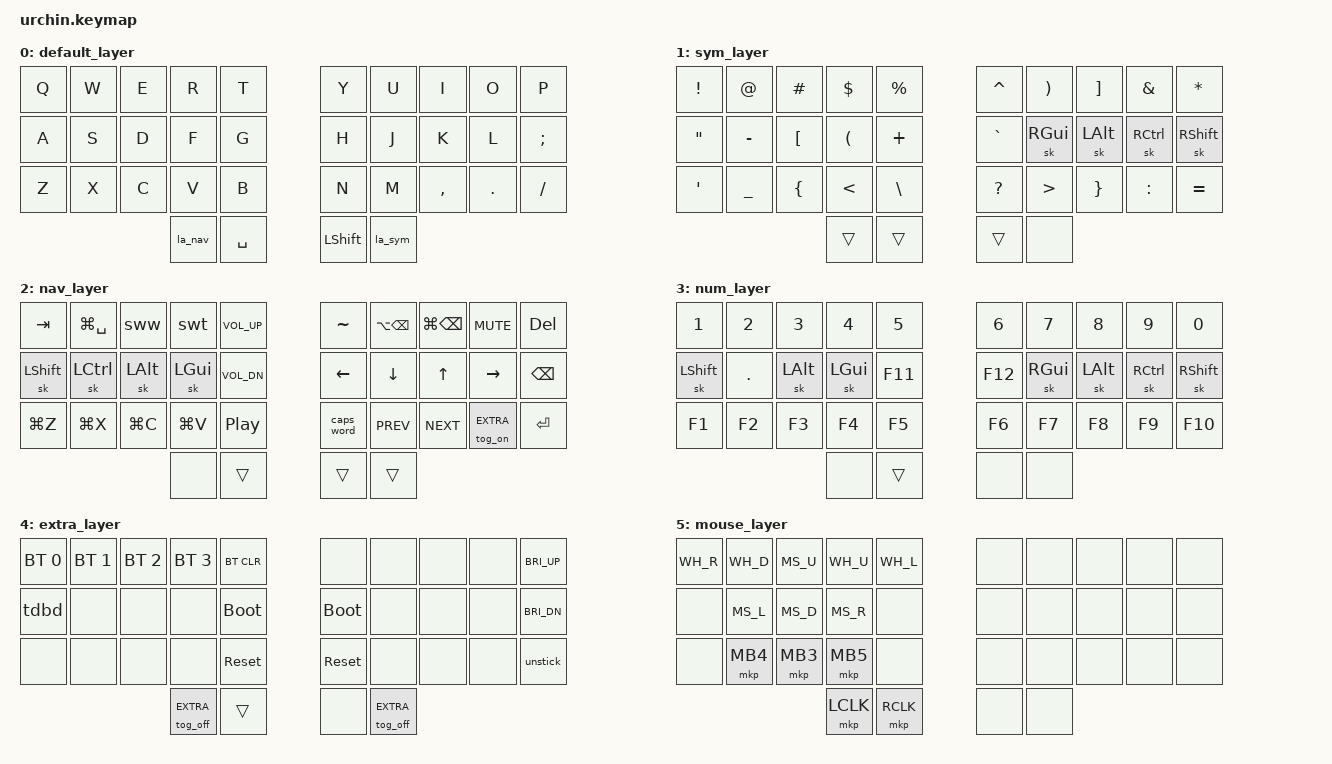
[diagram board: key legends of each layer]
#include <behaviors.dtsi>
#include <dt-bindings/zmk/keys.h>
#include <dt-bindings/zmk/bt.h>
#include <dt-bindings/zmk/outputs.h>
#include <dt-bindings/zmk/keys.h>
#include "mouse.dtsi"

// Layers from the QMK config
#define BASE  0
#define SYM   1
#define NAV   2
#define NUM   3
#define EXTRA 4
#define MOUSE 5

// QMK-ish aliases
#define XXX &none
#define ___ &trans

#define CMDBSPC  &kp LG(BSPC)
#define ALTBSPC  &kp LA(BSPC)
#define CMDZ     &kp LG(Z)
#define CMDX     &kp LG(X)
#define CMDC     &kp LG(C)
#define CMDV     &kp LG(V)
#define SWPL     &kp LG(SPACE)

&caps_word {
    continue-list = <MINUS BSPC DEL UNDER F22>; // F22 is required for layers
};

&sk {
    release-after-ms = <100000000>; // indefinite
    quick-release; // modifiers are ignored so that would not become a problem
	ignore-modifiers;
};

/ {
    combos {
        compatible = "zmk,combos";
        combo_weEsc {
            timeout-ms = <40>;
            require-prior-idle-ms = <150>;
            key-positions = <1 2>; // we
            bindings = <&kp ESC>;
            layers = <BASE>;
        };

        combo_hjGJ {
            timeout-ms = <40>;
            require-prior-idle-ms = <150>;
            key-positions = <15 16>; // hj
            bindings = <&kp LG(J)>;
            layers = <BASE>;
        };

        combo_wrMouse {
            timeout-ms = <40>;
            require-prior-idle-ms = <200>;
            key-positions = <1 3>; // wr
            bindings = <&smart_mouse>;
            layers = <BASE>;
            slow-release;
        };

        combo_uoExtra {
            timeout-ms = <40>;
            require-prior-idle-ms = <200>;
            key-positions = <6 8>; // uo
            bindings = <&tog EXTRA>;
            slow-release;
        };
    };

    macros {
        la_nav: cancel_queued_os_mods_and_toggle_nav {
            compatible = "zmk,behavior-macro";
            #binding-cells = <0>;
            bindings
                = <&macro_press &mo NAV>
                , <&macro_tap &kp F22>
                , <&macro_pause_for_release>
                , <&macro_release &mo NAV>
                ;
        };

        la_sym: cancel_queued_os_mods_and_toggle_sym {
            compatible = "zmk,behavior-macro";
            #binding-cells = <0>;
            bindings
                = <&macro_press &mo SYM>
                , <&macro_tap &kp F22>
                , <&macro_pause_for_release>
                , <&macro_release &mo SYM>
                ;
        };

		unstick: unstick_mods {
			compatible = "zmk,behavior-macro";
			#binding-cells = <0>;
			bindings = <&kp LSHIFT &kp RSHIFT &kp LCTRL &kp RCTRL &kp LALT &kp RALT &kp LGUI &kp RGUI>;
		};
    };

    behaviors {
        sww: swap_window {
            compatible = "zmk,behavior-tri-state";
            #binding-cells = <0>;
            bindings = <&kt LGUI>, <&kp TAB>, <&kt LGUI>;
            ignored-key-positions = <10 32>; // left hand shift, right thumb shift
        };

        swt: swap_tab {
            compatible = "zmk,behavior-tri-state";
            #binding-cells = <0>;
            bindings = <&kt LCTRL>, <&kp TAB>, <&kt LCTRL>;
            ignored-key-positions = <10 32>;
        };

        smart_mouse: smart_mouse {
            compatible = "zmk,behavior-tri-state";
            #binding-cells = <0>;
            bindings = <&tog MOUSE>, <XXX>, <&tog MOUSE>;
            ignored-key-positions = <30 31 0 1 2 3 4 11 12 13 21 22 23>;
            ignored-layers = <MOUSE>;
        };

        tdbd: tap_dance_bt_disable {
            compatible = "zmk,behavior-tap-dance";
            #binding-cells = <0>;
            tapping-term-ms = <200>;
            bindings = <&bt BT_DISC 0>, <&bt BT_DISC 1>, <&bt BT_DISC 2>, <&bt BT_DISC 3>;
        };

        tog_on: toggle_layer_on_only {
            compatible = "zmk,behavior-toggle-layer";
            #binding-cells = <1>;
            toggle-mode = "on";
        };

        tog_off: toggle_layer_off_only {
            compatible = "zmk,behavior-toggle-layer";
            #binding-cells = <1>;
            toggle-mode = "off";
        };
    };

    conditional_layers {
        compatible = "zmk,conditional-layers";
        tri_layer {
            if-layers = <SYM NAV>;
            then-layer = <NUM>;
        };
    };

    keymap {
        compatible = "zmk,keymap";
		default_layer {
			bindings = <
			&kp Q &kp W &kp E &kp R &kp T           &kp Y &kp U  &kp I     &kp O   &kp P
			&kp A &kp S &kp D &kp F &kp G           &kp H &kp J  &kp K     &kp L   &kp SEMI
			&kp Z &kp X &kp C &kp V &kp B           &kp N &kp M  &kp COMMA &kp DOT &kp SLASH
				        &la_nav &kp SPACE           &kp LSHFT &la_sym
			>;
		};

		sym_layer {
			bindings = <
			&kp EXCL &kp AT    &kp HASH &kp DLLR &kp PRCNT          &kp CARET &kp RPAR &kp RBKT &kp AMPS  &kp STAR
			&kp DQT  &kp MINUS &kp LBKT &kp LPAR &kp PLUS           &kp GRAVE &sk RGUI &sk LALT &sk RCTRL &sk RSHFT // avoid RALT
			&kp SQT  &kp UNDER &kp LBRC &kp LT   &kp BSLH           &kp QMARK &kp GT   &kp RBRC &kp COLON &kp EQUAL
				                                  ___ ___           ___ XXX
			>;
		};

		nav_layer {
			bindings = <
			&kp TAB   SWPL      &sww     &swt      &kp C_VOL_UP      &kp TILDE  ALTBSPC    CMDBSPC    &kp K_MUTE    &kp DEL
			&sk LSHFT &sk LCTRL &sk LALT &sk LGUI  &kp C_VOL_DN      &kp LEFT   &kp DOWN   &kp UP     &kp RIGHT     &kp BSPC
			CMDZ      CMDX      CMDC     CMDV      &kp C_PP          &caps_word &kp C_PREV &kp C_NEXT &tog_on EXTRA &kp ENTER
				                                        XXX ___      ___ ___
			>;
		};

		num_layer {
			bindings = <
			&kp N1    &kp N2  &kp N3   &kp N4   &kp N5            &kp N6  &kp N7   &kp N8   &kp N9    &kp N0
			&sk LSHFT &kp DOT &sk LALT &sk LGUI &kp F11           &kp F12 &sk RGUI &sk LALT &sk RCTRL &sk RSHFT // avoid RALT
			&kp F1    &kp F2  &kp F3   &kp F4   &kp F5            &kp F6  &kp F7   &kp F8   &kp F9    &kp F10
				                                XXX ___           XXX XXX
			>;
		};

		extra_layer {
			bindings = <
			&bt BT_SEL 0 &bt BT_SEL 1 &bt BT_SEL 2 &bt BT_SEL 3 &bt BT_CLR            XXX         XXX XXX XXX &kp C_BRI_UP
			&tdbd        XXX          XXX          XXX          &bootloader           &bootloader XXX XXX XXX &kp C_BRI_DN
			XXX          XXX          XXX          XXX          &sys_reset            &sys_reset  XXX XXX XXX &unstick
				                                        &tog_off EXTRA ___            XXX &tog_off EXTRA
			>;
		};

        mouse_layer {
			bindings = <
			WH_R WH_D     MS_U     WH_U     WH_L      XXX XXX XXX XXX XXX
			XXX  MS_L     MS_D     MS_R     XXX       XXX XXX XXX XXX XXX
			XXX  &mkp MB4 &mkp MB3 &mkp MB5 XXX       XXX XXX XXX XXX XXX
				            &mkp LCLK &mkp RCLK       XXX XXX
			>;
        };
    };
};
